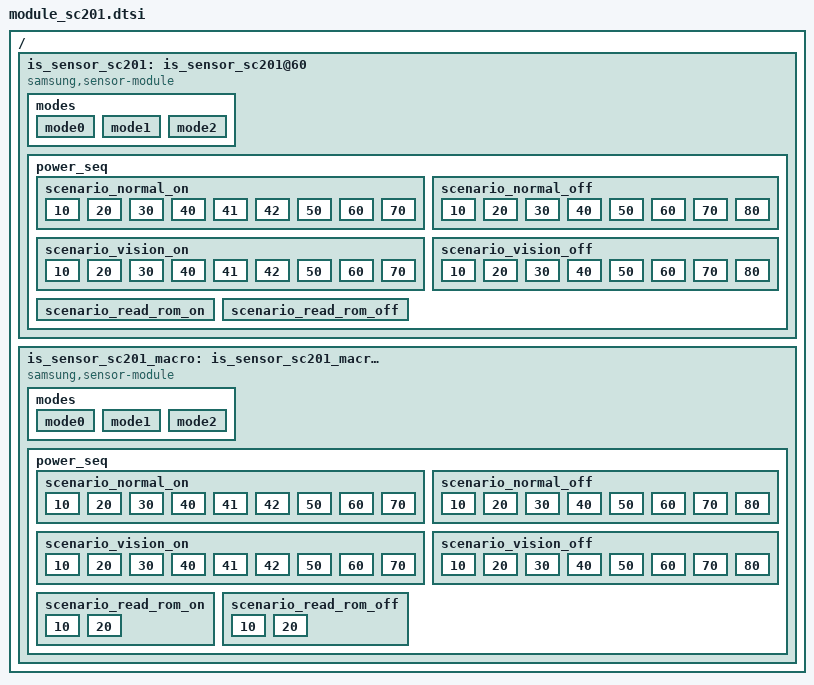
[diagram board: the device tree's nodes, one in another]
/*
 * SAMSUNG EXYNOSxxxx board camera device tree source
 *
 * Copyright (c) 2021 Samsung Electronics Co., Ltd.
 *		http://www.samsung.com
 *
 * This program is free software; you can redistribute it and/or modify
 * it under the terms of the GNU General Public License version 2 as
 * published by the Free Software Foundation.
 */

#include <dt-bindings/camera/exynos_is_dt.h>

/ {
	fragment@camera {
		target-path = "/";
		__overlay__ {
			is_sensor_sc201: is_sensor_sc201@60 {
				compatible = "samsung,sensor-module";

				/* common */
				sensor_id = <SENSOR_NAME_SC201>;
				active_width = <1600>;
				active_height = <1200>;
				margin_left = <0>;
				margin_right = <0>;
				margin_top = <0>;
				margin_bottom = <0>;
				max_framerate = <60>;
				bitwidth = <10>;
				use_retention_mode = <SENSOR_RETENTION_INACTIVE>;
				sensor_maker = "SmartSens";
				sensor_name = "SC201";
				setfile_name = "setfile_sc201.bin";
				sensor_module_type = <SENSOR_TYPE_MONO>;
				pinning_setfile;
				preload_setfile;

				status = "okay";

				/* board */
				pinctrl-names = "pin0", "pin1", "pin2", "release";
				pinctrl-0 = <>;
				pinctrl-1 = <&sensor_mclk1_out>;
				pinctrl-2 = <&sensor_mclk1_fn>;
				pinctrl-3 = <>;

				position = <2>; /* Rear:0. Front:1, Tele:2 */
				id = <2>; /* is_sensor id */
				mclk_ch = <1>;
				sensor_i2c_ch = <3>; /* SENSOR_CONTROL_I2C3 */

				/* vendor */
				rom_type = <3>; /* ROM_TYPE_OTPROM */
				rom_id = <2>;
				rom_cal_index = <0>;
				/* sensor modes */
				modes {
						/* common = <width, height, fps, settle, mode, lane, speed, interleave, lrte, pd_mode> */
						/* vcX = <map, hwformat, width, height, hwformat, type, width, height> */

					/* 0 : 1600x1200@30fps 4:3 */
					mode0 {
						common = <1600 1200 30 0 0 CSI_DATA_LANES_1 715 CSI_MODE_VC_ONLY LRTE_DISABLE PD_NONE EX_NONE>;
						vc0 = </* in */ 0 HW_FORMAT_RAW10 1600 1200	/* out */ HW_FORMAT_RAW10 VC_NOTHING 1600 1200>;
						vc1 = </* in */ 1 HW_FORMAT_UNKNOWN 0 0		/* out */ HW_FORMAT_UNKNOWN VC_NOTHING 0 0>;
						vc2 = </* in */ 2 HW_FORMAT_UNKNOWN 0 0		/* out */ HW_FORMAT_UNKNOWN VC_NOTHING 0 0>;
						vc3 = </* in */ 3 HW_FORMAT_UNKNOWN 0 0		/* out */ HW_FORMAT_UNKNOWN VC_NOTHING 0 0>;
					};
					mode1 {
						common = <1600 900 30 0 1 CSI_DATA_LANES_1 715 CSI_MODE_VC_ONLY LRTE_DISABLE PD_NONE EX_NONE>;
						vc0 = </* in */ 0 HW_FORMAT_RAW10 1600 900	/* out */ HW_FORMAT_RAW10 VC_NOTHING 1600 900>;
						vc1 = </* in */ 1 HW_FORMAT_UNKNOWN 0 0		/* out */ HW_FORMAT_UNKNOWN VC_NOTHING 0 0>;
						vc2 = </* in */ 2 HW_FORMAT_UNKNOWN 0 0		/* out */ HW_FORMAT_UNKNOWN VC_NOTHING 0 0>;
						vc3 = </* in */ 3 HW_FORMAT_UNKNOWN 0 0		/* out */ HW_FORMAT_UNKNOWN VC_NOTHING 0 0>;
					};
					/* 2 : 800x600@60fps 4:3 */
					mode2 {
						common = <800 600 60 0 2 CSI_DATA_LANES_1 715 CSI_MODE_VC_ONLY LRTE_DISABLE PD_NONE EX_NONE>;
						vc0 = </* in */ 0 HW_FORMAT_RAW10 800 600	/* out */ HW_FORMAT_RAW10 VC_NOTHING 800 600>;
						vc1 = </* in */ 1 HW_FORMAT_UNKNOWN 0 0		/* out */ HW_FORMAT_UNKNOWN VC_NOTHING 0 0>;
						vc2 = </* in */ 2 HW_FORMAT_UNKNOWN 0 0		/* out */ HW_FORMAT_UNKNOWN VC_NOTHING 0 0>;
						vc3 = </* in */ 3 HW_FORMAT_UNKNOWN 0 0		/* out */ HW_FORMAT_UNKNOWN VC_NOTHING 0 0>;
					};
				};

				power_seq {
					use = <1>;
					gpio_mclk = <&gpg0 3 0x1>;
					scenario_normal_on {
						sensor_scenario = <SENSOR_SCENARIO_NORMAL>;
						gpio_scenario = <GPIO_SCENARIO_ON>;

						/* A start node number should be over the 10 for reserved number 0~9. */
						/* pname = "name"; pin = <act value dealy voltage>; gpio = <gpx# # 0x1>; */

						10 { pname = "sen_rst_low"; pin = <PIN_OUTPUT 0 0>; gpio = <&gpm8 0 0x1>; };
						20 { pname = "CAM_VDDIO_1P8_EN"; pin = <PIN_OUTPUT 1 2000>; gpio = <&gpp0 5 0x1>; };
						30 { pname = "VDD_FCAM_AVDD_2P8"; pin = <PIN_OUTPUT 1 1000>; gpio = <&gpp1 2 0x1>; };
						40 { pname = "sen_rst_high"; pin = <PIN_OUTPUT 1 1500>; gpio = <&gpm8 0 0x1>; };
						41 { pname = "sen_rst_low"; pin = <PIN_OUTPUT 0 1500>; gpio = <&gpm8 0 0x1>; };
						42 { pname = "sen_rst_high"; pin = <PIN_OUTPUT 1 2000>; gpio = <&gpm8 0 0x1>; };
						50 { pname = "pin"; pin = <PIN_FUNCTION 2 0>; };
						60 { pname = "MCLK"; pin = <PIN_MCLK 1 12000>; gpio = <&gpg0 3 0x1>; };
						70 { pname = "on_i2c"; pin = <PIN_I2C 1 0>; };
					};

					scenario_normal_off {
						sensor_scenario = <SENSOR_SCENARIO_NORMAL>;
						gpio_scenario = <GPIO_SCENARIO_OFF>;

						/* A start node number should be over the 10 for reserved number 0~9. */
						/* pname = "name"; pin = <act value dealy voltage>; gpio = <gpx# # 0x1>; */
						10 { pname = "off_i2c"; pin = <PIN_I2C 0 0>; };
						20 { pname = "MCLK"; pin = <PIN_MCLK 0 0>; gpio = <&gpg0 3 0x1>; };
						30 { pname = "sen_rst_low"; pin = <PIN_OUTPUT 0 500>; gpio = <&gpm8 0 0x1>; };
						40 { pname = "VDD_FCAM_AVDD_2P8"; pin = <PIN_OUTPUT 0 1000>; gpio = <&gpp1 2 0x1>; };
						50 { pname = "CAM_VDDIO_1P8_EN"; pin = <PIN_OUTPUT 0 0>; gpio = <&gpp0 5 0x1>; };
						60 { pname = "pin"; pin = <PIN_FUNCTION 0 0>; };
						70 { pname = "pin"; pin = <PIN_FUNCTION 1 0>; };
						80 { pname = "pin"; pin = <PIN_FUNCTION 0 500>; };
					};

					scenario_vision_on {
						sensor_scenario = <SENSOR_SCENARIO_VISION>;
						gpio_scenario = <GPIO_SCENARIO_ON>;

						/* A start node number should be over the 10 for reserved number 0~9. */
						/* pname = "name"; pin = <act value dealy voltage>; gpio = <gpx# # 0x1>; */

						10 { pname = "sen_rst_low"; pin = <PIN_OUTPUT 0 0>; gpio = <&gpm8 0 0x1>; };
						20 { pname = "CAM_VDDIO_1P8_EN"; pin = <PIN_OUTPUT 1 2000>; gpio = <&gpp0 5 0x1>; };
						30 { pname = "VDD_FCAM_AVDD_2P8"; pin = <PIN_OUTPUT 1 1000>; gpio = <&gpp1 2 0x1>; };
						40 { pname = "sen_rst_high"; pin = <PIN_OUTPUT 1 1500>; gpio = <&gpm8 0 0x1>; };
						41 { pname = "sen_rst_low"; pin = <PIN_OUTPUT 0 1500>; gpio = <&gpm8 0 0x1>; };
						42 { pname = "sen_rst_high"; pin = <PIN_OUTPUT 1 2000>; gpio = <&gpm8 0 0x1>; };
						50 { pname = "pin"; pin = <PIN_FUNCTION 2 0>; };
						60 { pname = "MCLK"; pin = <PIN_MCLK 1 12000>; gpio = <&gpg0 3 0x1>; };
						70 { pname = "on_i2c"; pin = <PIN_I2C 1 0>; };
					};

					scenario_vision_off {
						sensor_scenario = <SENSOR_SCENARIO_VISION>;
						gpio_scenario = <GPIO_SCENARIO_OFF>;

						/* A start node number should be over the 10 for reserved number 0~9. */
						/* pname = "name"; pin = <act value dealy voltage>; gpio = <gpx# # 0x1>; */
						10 { pname = "off_i2c"; pin = <PIN_I2C 0 0>; };
						20 { pname = "MCLK"; pin = <PIN_MCLK 0 0>; gpio = <&gpg0 3 0x1>; };
						30 { pname = "sen_rst_low"; pin = <PIN_OUTPUT 0 500>; gpio = <&gpm8 0 0x1>; };
						40 { pname = "VDD_FCAM_AVDD_2P8"; pin = <PIN_OUTPUT 0 1000>; gpio = <&gpp1 2 0x1>; };
						50 { pname = "CAM_VDDIO_1P8_EN"; pin = <PIN_OUTPUT 0 0>; gpio = <&gpp0 5 0x1>; };
						60 { pname = "pin"; pin = <PIN_FUNCTION 0 0>; };
						70 { pname = "pin"; pin = <PIN_FUNCTION 1 0>; };
						80 { pname = "pin"; pin = <PIN_FUNCTION 0 500>; };
					};

					scenario_read_rom_on {
						sensor_scenario = <SENSOR_SCENARIO_READ_ROM>;
						gpio_scenario = <GPIO_SCENARIO_ON>;

					};

					scenario_read_rom_off {
						sensor_scenario = <SENSOR_SCENARIO_READ_ROM>;
						gpio_scenario = <GPIO_SCENARIO_OFF>;

					};
				};
			};

			is_sensor_sc201_macro: is_sensor_sc201_macro@64 {
				compatible = "samsung,sensor-module";

				/* common */
				sensor_id = <SENSOR_NAME_SC201>;
				active_width = <1600>;
				active_height = <1200>;
				margin_left = <0>;
				margin_right = <0>;
				margin_top = <0>;
				margin_bottom = <0>;
				max_framerate = <60>;
				bitwidth = <10>;
				use_retention_mode = <SENSOR_RETENTION_INACTIVE>;
				sensor_maker = "SMARTSENS";
				sensor_name = "SC201";
				setfile_name = "setfile_sc201_macro.bin";

				status = "okay";

				/* board */
				pinctrl-names = "pin0", "pin1", "pin2", "release";
				pinctrl-0 = <>;
				pinctrl-1 = <&sensor_mclk1_out>;
				pinctrl-2 = <&sensor_mclk1_fn>;
				pinctrl-3 = <>;

				position = <6>; /* Rear:0. Front:1, Bokeh:2, UW:4, Macro:6*/
				id = <3>; /* is_sensor id */

				mclk_ch = <1>;
				sensor_i2c_ch = <3>; /* SENSOR_CONTROL_I2C3 */

				/* vendor */
				rom_type = <2>; /* ROM_TYPE_EEPROM */
				rom_id = <6>;
				rom_cal_index = <0>;

				/* sensor modes */
				modes {
						/* common = <width, height, fps, settle, mode, lane, speed, interleave, lrte, pd_mode> */
						/* vcX = <map, hwformat, width, height, hwformat, type, width, height> */

					/* 0 : 1600x1200@30fps 4:3 */
					mode0 {
						common = <1600 1200 30 0 0 CSI_DATA_LANES_1 676 CSI_MODE_VC_ONLY LRTE_DISABLE PD_NONE EX_NONE>;
						vc0 = </* in */ 0 HW_FORMAT_RAW10 1600 1200	/* out */ HW_FORMAT_RAW10 VC_NOTHING 0 0>;
						vc1 = </* in */ 1 HW_FORMAT_UNKNOWN 0 0		/* out */ HW_FORMAT_UNKNOWN VC_NOTHING 0 0>;
						vc2 = </* in */ 2 HW_FORMAT_UNKNOWN 0 0		/* out */ HW_FORMAT_UNKNOWN VC_NOTHING 0 0>;
						vc3 = </* in */ 3 HW_FORMAT_UNKNOWN 0 0		/* out */ HW_FORMAT_UNKNOWN VC_NOTHING 0 0>;
					};
					/* 1 : 1600x900@30fps 16:9 */
					mode1 {
						common = <1600 900 30 0 1 CSI_DATA_LANES_1 676 CSI_MODE_VC_ONLY LRTE_DISABLE PD_NONE EX_NONE>;
						vc0 = </* in */ 0 HW_FORMAT_RAW10 1600 900	/* out */ HW_FORMAT_RAW10 VC_NOTHING 0 0>;
						vc1 = </* in */ 1 HW_FORMAT_UNKNOWN 0 0		/* out */ HW_FORMAT_UNKNOWN VC_NOTHING 0 0>;
						vc2 = </* in */ 2 HW_FORMAT_UNKNOWN 0 0		/* out */ HW_FORMAT_UNKNOWN VC_NOTHING 0 0>;
						vc3 = </* in */ 3 HW_FORMAT_UNKNOWN 0 0		/* out */ HW_FORMAT_UNKNOWN VC_NOTHING 0 0>;
					};
					/* 2 : 800x600@60fps Fasten AE */
					mode2 {
						common = <800 600 60 0 2 CSI_DATA_LANES_1 676 CSI_MODE_VC_ONLY LRTE_DISABLE PD_NONE EX_NONE>;
						vc0 = </* in */ 0 HW_FORMAT_RAW10 800 600	/* out */ HW_FORMAT_RAW10 VC_NOTHING 0 0>;
						vc1 = </* in */ 1 HW_FORMAT_UNKNOWN 0 0		/* out */ HW_FORMAT_UNKNOWN VC_NOTHING 0 0>;
						vc2 = </* in */ 2 HW_FORMAT_UNKNOWN 0 0		/* out */ HW_FORMAT_UNKNOWN VC_NOTHING 0 0>;
						vc3 = </* in */ 3 HW_FORMAT_UNKNOWN 0 0		/* out */ HW_FORMAT_UNKNOWN VC_NOTHING 0 0>;
					};
				};

				power_seq {
					use = <1>;
					gpio_mclk = <&gpg0 3 0x1>;
					scenario_normal_on {
						sensor_scenario = <SENSOR_SCENARIO_NORMAL>;
						gpio_scenario = <GPIO_SCENARIO_ON>;

						/* A start node number should be over the 10 for reserved number 0~9. */
						/* pname = "name"; pin = <act value dealy voltage>; gpio = <gpx# # 0x1>; */

						10 { pname = "sen_rst_low"; pin = <PIN_OUTPUT 0 0>; gpio = <&gpg1 2 0x1>; };
						20 { pname = "CAM_VDDIO_1P8_EN"; pin = <PIN_OUTPUT 1 2000>; gpio = <&gpp0 5 0x1>; };
						30 { pname = "VDD_FCAM_AVDD_2P8"; pin = <PIN_OUTPUT 1 1000>; gpio = <&gpp1 2 0x1>; };
						40 { pname = "sen_rst_high"; pin = <PIN_OUTPUT 1 1500>; gpio = <&gpg1 2 0x1>; };
						41 { pname = "sen_rst_low"; pin = <PIN_OUTPUT 0 1500>; gpio = <&gpg1 2 0x1>; };
						42 { pname = "sen_rst_high"; pin = <PIN_OUTPUT 1 2000>; gpio = <&gpg1 2 0x1>; };
						50 { pname = "pin"; pin = <PIN_FUNCTION 2 0>; };
						60 { pname = "MCLK"; pin = <PIN_MCLK 1 12000>; gpio = <&gpg0 3 0x1>; };
						70 { pname = "on_i2c"; pin = <PIN_I2C 1 0>; };
					};

					scenario_normal_off {
						sensor_scenario = <SENSOR_SCENARIO_NORMAL>;
						gpio_scenario = <GPIO_SCENARIO_OFF>;

						/* A start node number should be over the 10 for reserved number 0~9. */
						/* pname = "name"; pin = <act value dealy voltage>; gpio = <gpx# # 0x1>; */
						10 { pname = "off_i2c"; pin = <PIN_I2C 0 0>; };
						20 { pname = "MCLK"; pin = <PIN_MCLK 0 0>; gpio = <&gpg0 3 0x1>; };
						30 { pname = "sen_rst_low"; pin = <PIN_OUTPUT 0 500>; gpio = <&gpg1 2 0x1>; };
						40 { pname = "VDD_FCAM_AVDD_2P8"; pin = <PIN_OUTPUT 0 1000>; gpio = <&gpp1 2 0x1>; };
						50 { pname = "CAM_VDDIO_1P8_EN"; pin = <PIN_OUTPUT 0 0>; gpio = <&gpp0 5 0x1>; };
						60 { pname = "pin"; pin = <PIN_FUNCTION 0 0>; };
						70 { pname = "pin"; pin = <PIN_FUNCTION 1 0>; };
						80 { pname = "pin"; pin = <PIN_FUNCTION 0 500>; };
					};

					scenario_vision_on {
						sensor_scenario = <SENSOR_SCENARIO_VISION>;
						gpio_scenario = <GPIO_SCENARIO_ON>;

						/* A start node number should be over the 10 for reserved number 0~9. */
						/* pname = "name"; pin = <act value dealy voltage>; gpio = <gpx# # 0x1>; */

						10 { pname = "sen_rst_low"; pin = <PIN_OUTPUT 0 0>; gpio = <&gpg1 2 0x1>; };
						20 { pname = "CAM_VDDIO_1P8_EN"; pin = <PIN_OUTPUT 1 2000>; gpio = <&gpp0 5 0x1>; };
						30 { pname = "VDD_FCAM_AVDD_2P8"; pin = <PIN_OUTPUT 1 1000>; gpio = <&gpp1 2 0x1>; };
						40 { pname = "sen_rst_high"; pin = <PIN_OUTPUT 1 1500>; gpio = <&gpg1 2 0x1>; };
						41 { pname = "sen_rst_low"; pin = <PIN_OUTPUT 0 1500>; gpio = <&gpg1 2 0x1>; };
						42 { pname = "sen_rst_high"; pin = <PIN_OUTPUT 1 2000>; gpio = <&gpg1 2 0x1>; };
						50 { pname = "pin"; pin = <PIN_FUNCTION 2 0>; };
						60 { pname = "MCLK"; pin = <PIN_MCLK 1 12000>; gpio = <&gpg0 3 0x1>; };
						70 { pname = "on_i2c"; pin = <PIN_I2C 1 0>; };
					};

					scenario_vision_off {
						sensor_scenario = <SENSOR_SCENARIO_VISION>;
						gpio_scenario = <GPIO_SCENARIO_OFF>;

						/* A start node number should be over the 10 for reserved number 0~9. */
						/* pname = "name"; pin = <act value dealy voltage>; gpio = <gpx# # 0x1>; */
						10 { pname = "off_i2c"; pin = <PIN_I2C 0 0>; };
						20 { pname = "MCLK"; pin = <PIN_MCLK 0 0>; gpio = <&gpg0 3 0x1>; };
						30 { pname = "sen_rst_low"; pin = <PIN_OUTPUT 0 500>; gpio = <&gpg1 2 0x1>; };
						40 { pname = "VDD_FCAM_AVDD_2P8"; pin = <PIN_OUTPUT 0 1000>; gpio = <&gpp1 2 0x1>; };
						50 { pname = "CAM_VDDIO_1P8_EN"; pin = <PIN_OUTPUT 0 0>; gpio = <&gpp0 5 0x1>; };
						60 { pname = "pin"; pin = <PIN_FUNCTION 0 0>; };
						70 { pname = "pin"; pin = <PIN_FUNCTION 1 0>; };
						80 { pname = "pin"; pin = <PIN_FUNCTION 0 500>; };
					};

					scenario_read_rom_on {
						sensor_scenario = <SENSOR_SCENARIO_READ_ROM>;
						gpio_scenario = <GPIO_SCENARIO_ON>;

						/* A start node number should be over the 10 for reserved number 0~9. */
						/* pname = "name"; pin = <act value dealy voltage>; gpio = <gpx# # 0x1>; */
						10 { pname = "CAM_VDDIO_1P8_EN"; pin = <PIN_OUTPUT 1 2000>; gpio = <&gpp0 5 0x1>; };
						20 { pname = "on_i2c"; pin = <PIN_I2C 1 0>; };
					};

					scenario_read_rom_off {
						sensor_scenario = <SENSOR_SCENARIO_READ_ROM>;
						gpio_scenario = <GPIO_SCENARIO_OFF>;

						/* A start node number should be over the 10 for reserved number 0~9. */
						/* pname = "name"; pin = <act value dealy voltage>; gpio = <gpx# # 0x1>; */
						10 { pname = "off_i2c"; pin = <PIN_I2C 0 0>; };
						20 { pname = "CAM_VDDIO_1P8_EN"; pin = <PIN_OUTPUT 0 0>; gpio = <&gpp0 5 0x1>; };
					};
				};
			};
		}; /* end of __overlay__ */
	}; /* end of fragment */
}; /* end of root */
